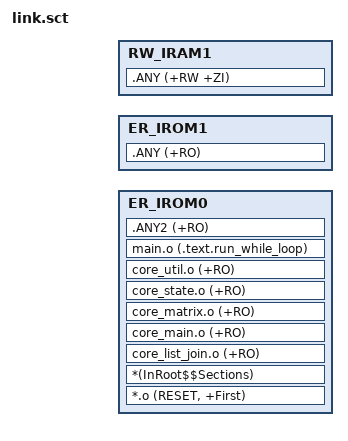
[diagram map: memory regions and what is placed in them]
#! armclang -E --target=arm-arm-none-eabi -mcpu=cortex-m33 -xc -I $SDK_ROOT/drivers/cmsis/sf32lb52x 
#include "rtconfig.h"
#include "mem_map.h"

; *************************************************************
; *** Scatter-Loading Description File generated by uVision ***
; *************************************************************

LR_IROM1 LCPU_RAM_CODE_START_ADDR LPSYS_RAM_SIZE {    ; load region size_region
  ER_IROM0 LCPU_RAM_CODE_START_ADDR LPSYS_RAM_SIZE  {  ; load address = execution address
   *.o (RESET, +First)
   *(InRoot$$Sections)
   core_list_join.o (+RO)
   core_main.o (+RO)
   core_matrix.o (+RO)
   core_state.o (+RO)
   core_util.o (+RO)
   main.o (.text.run_while_loop)
   .ANY2 (+RO)
  }
  ER_IROM1 +0   {  ; load address = execution address
   .ANY (+RO)
  }
  ScatterAssert((ImageLength(ER_IROM0)+ImageLength(ER_IROM1)+LCPU_MBOX_SIZE)<LPSYS_RAM_SIZE)

  RW_IRAM1 LPSYS_EM_BASE LPSYS_EM_SIZE  {  ; RW data
   .ANY (+RW +ZI)
  }  
}

